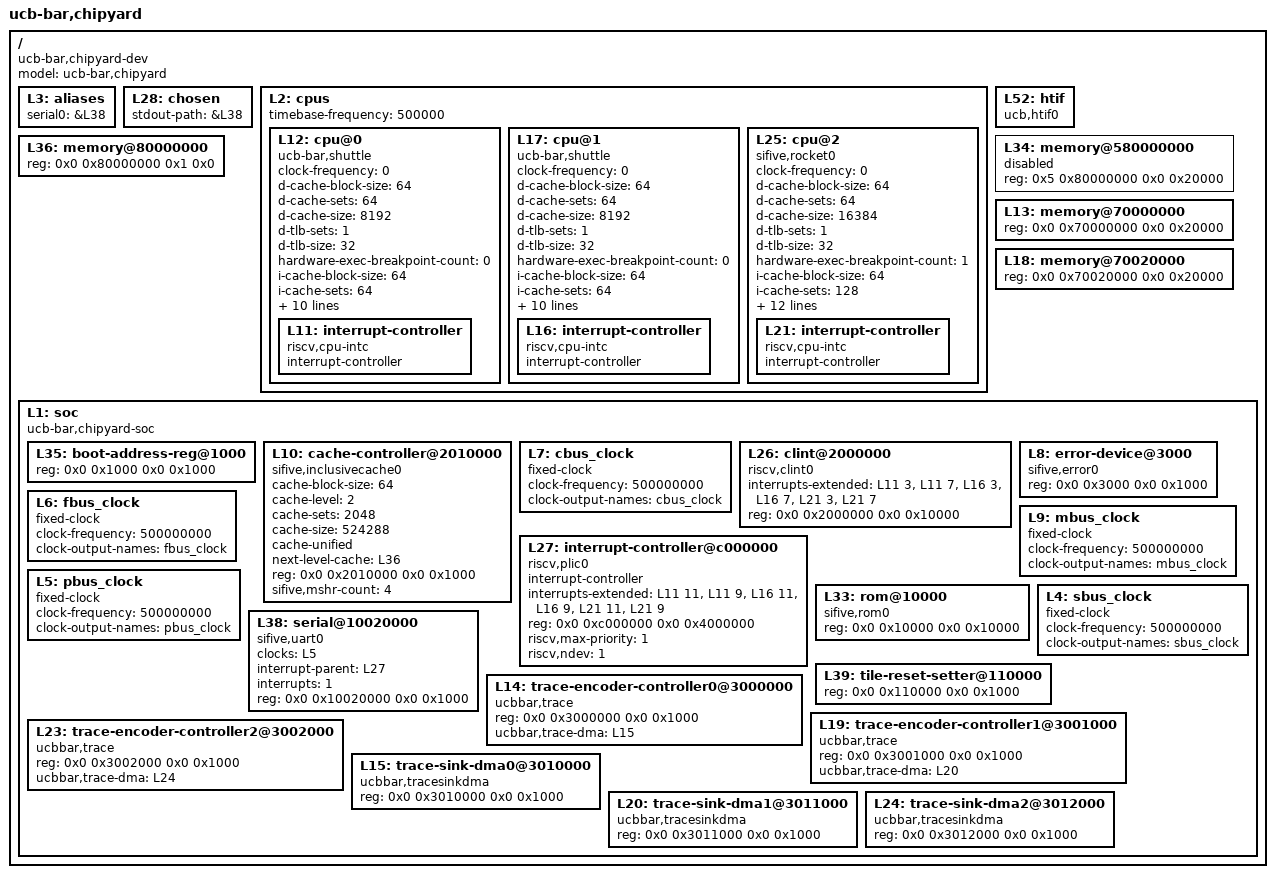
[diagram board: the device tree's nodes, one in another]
/dts-v1/;

/ {
	#address-cells = <2>;
	#size-cells = <2>;
	compatible = "ucb-bar,chipyard-dev";
	model = "ucb-bar,chipyard";
	L3: aliases {
		serial0 = &L38;
	};
	L28: chosen {
		stdout-path = &L38;
	};
	L2: cpus {
		#address-cells = <1>;
		#size-cells = <0>;
		timebase-frequency = <500000>;
		L12: cpu@0 {
			clock-frequency = <0>;
			compatible = "ucb-bar,shuttle", "riscv";
			d-cache-block-size = <64>;
			d-cache-sets = <64>;
			d-cache-size = <8192>;
			d-tlb-sets = <1>;
			d-tlb-size = <32>;
			device_type = "cpu";
			hardware-exec-breakpoint-count = <0>;
			i-cache-block-size = <64>;
			i-cache-sets = <64>;
			i-cache-size = <8192>;
			i-tlb-sets = <1>;
			i-tlb-size = <32>;
			mmu-type = "riscv,sv39";
			next-level-cache = <&L10>;
			reg = <0x0>;
			riscv,isa = "rv64imafdcbvzicsr_zifencei_zihpm_zvl256b_zve64d_zvfh_zfh_zba_zbb_zbs_zvbb_zvfofp8min_zfbfmin_zvfbfmin_zvfbfa_xsfmmbase_xsfmm32a8i_xsfmm32a8f_xsfmm32t";
			status = "okay";
			timebase-frequency = <500000>;
			tlb-split;
			L11: interrupt-controller {
				#interrupt-cells = <1>;
				compatible = "riscv,cpu-intc";
				interrupt-controller;
			};
		};
		L17: cpu@1 {
			clock-frequency = <0>;
			compatible = "ucb-bar,shuttle", "riscv";
			d-cache-block-size = <64>;
			d-cache-sets = <64>;
			d-cache-size = <8192>;
			d-tlb-sets = <1>;
			d-tlb-size = <32>;
			device_type = "cpu";
			hardware-exec-breakpoint-count = <0>;
			i-cache-block-size = <64>;
			i-cache-sets = <64>;
			i-cache-size = <8192>;
			i-tlb-sets = <1>;
			i-tlb-size = <32>;
			mmu-type = "riscv,sv39";
			next-level-cache = <&L10>;
			reg = <0x1>;
			riscv,isa = "rv64imafdcbvzicsr_zifencei_zihpm_zvl256b_zve64d_zvfh_zfh_zba_zbb_zbs_zvbb_zvfofp8min_zfbfmin_zvfbfmin_zvfbfa_xsfmmbase_xsfmm32a8i_xsfmm32a8f_xsfmm32t";
			status = "okay";
			timebase-frequency = <500000>;
			tlb-split;
			L16: interrupt-controller {
				#interrupt-cells = <1>;
				compatible = "riscv,cpu-intc";
				interrupt-controller;
			};
		};
		L25: cpu@2 {
			clock-frequency = <0>;
			compatible = "sifive,rocket0", "riscv";
			d-cache-block-size = <64>;
			d-cache-sets = <64>;
			d-cache-size = <16384>;
			d-tlb-sets = <1>;
			d-tlb-size = <32>;
			device_type = "cpu";
			hardware-exec-breakpoint-count = <1>;
			i-cache-block-size = <64>;
			i-cache-sets = <128>;
			i-cache-size = <16384>;
			i-tlb-sets = <1>;
			i-tlb-size = <32>;
			mmu-type = "riscv,sv39";
			next-level-cache = <&L10>;
			reg = <0x2>;
			riscv,isa = "rv64imafdcvzicsr_zifencei_zihpm_zvl256b_zve64d_zvfh_zfh_zvbb_xrocket";
			riscv,pmpgranularity = <4>;
			riscv,pmpregions = <8>;
			status = "okay";
			timebase-frequency = <500000>;
			tlb-split;
			L21: interrupt-controller {
				#interrupt-cells = <1>;
				compatible = "riscv,cpu-intc";
				interrupt-controller;
			};
		};
	};
	L52: htif {
		compatible = "ucb,htif0";
	};
	L34: memory@580000000 {
		device_type = "memory";
		reg = <0x5 0x80000000 0x0 0x20000>;
		status = "disabled";
	};
	L13: memory@70000000 {
		device_type = "memory";
		reg = <0x0 0x70000000 0x0 0x20000>;
	};
	L18: memory@70020000 {
		device_type = "memory";
		reg = <0x0 0x70020000 0x0 0x20000>;
	};
	L36: memory@80000000 {
		device_type = "memory";
		reg = <0x0 0x80000000 0x1 0x0>;
	};
	L1: soc {
		#address-cells = <2>;
		#size-cells = <2>;
		compatible = "ucb-bar,chipyard-soc", "simple-bus";
		ranges;
		L35: boot-address-reg@1000 {
			reg = <0x0 0x1000 0x0 0x1000>;
			reg-names = "control";
		};
		L10: cache-controller@2010000 {
			cache-block-size = <64>;
			cache-level = <2>;
			cache-sets = <2048>;
			cache-size = <524288>;
			cache-unified;
			compatible = "sifive,inclusivecache0", "cache";
			next-level-cache = <&L36>;
			reg = <0x0 0x2010000 0x0 0x1000>;
			reg-names = "control";
			sifive,mshr-count = <4>;
		};
		L7: cbus_clock {
			#clock-cells = <0>;
			clock-frequency = <500000000>;
			clock-output-names = "cbus_clock";
			compatible = "fixed-clock";
		};
		L26: clint@2000000 {
			compatible = "riscv,clint0";
			interrupts-extended = <&L11 3 &L11 7 &L16 3 &L16 7 &L21 3 &L21 7>;
			reg = <0x0 0x2000000 0x0 0x10000>;
			reg-names = "control";
		};
		L8: error-device@3000 {
			compatible = "sifive,error0";
			reg = <0x0 0x3000 0x0 0x1000>;
		};
		L6: fbus_clock {
			#clock-cells = <0>;
			clock-frequency = <500000000>;
			clock-output-names = "fbus_clock";
			compatible = "fixed-clock";
		};
		L27: interrupt-controller@c000000 {
			#interrupt-cells = <1>;
			compatible = "riscv,plic0";
			interrupt-controller;
			interrupts-extended = <&L11 11 &L11 9 &L16 11 &L16 9 &L21 11 &L21 9>;
			reg = <0x0 0xc000000 0x0 0x4000000>;
			reg-names = "control";
			riscv,max-priority = <1>;
			riscv,ndev = <1>;
		};
		L9: mbus_clock {
			#clock-cells = <0>;
			clock-frequency = <500000000>;
			clock-output-names = "mbus_clock";
			compatible = "fixed-clock";
		};
		L5: pbus_clock {
			#clock-cells = <0>;
			clock-frequency = <500000000>;
			clock-output-names = "pbus_clock";
			compatible = "fixed-clock";
		};
		L33: rom@10000 {
			compatible = "sifive,rom0";
			reg = <0x0 0x10000 0x0 0x10000>;
			reg-names = "mem";
		};
		L4: sbus_clock {
			#clock-cells = <0>;
			clock-frequency = <500000000>;
			clock-output-names = "sbus_clock";
			compatible = "fixed-clock";
		};
		L38: serial@10020000 {
			clocks = <&L5>;
			compatible = "sifive,uart0";
			interrupt-parent = <&L27>;
			interrupts = <1>;
			reg = <0x0 0x10020000 0x0 0x1000>;
			reg-names = "control";
		};
		L39: tile-reset-setter@110000 {
			reg = <0x0 0x110000 0x0 0x1000>;
			reg-names = "control";
		};
		L14: trace-encoder-controller0@3000000 {
			compatible = "ucbbar,trace";
			reg = <0x0 0x3000000 0x0 0x1000>;
			reg-names = "control";
			ucbbar,trace-dma = <&L15>;
		};
		L19: trace-encoder-controller1@3001000 {
			compatible = "ucbbar,trace";
			reg = <0x0 0x3001000 0x0 0x1000>;
			reg-names = "control";
			ucbbar,trace-dma = <&L20>;
		};
		L23: trace-encoder-controller2@3002000 {
			compatible = "ucbbar,trace";
			reg = <0x0 0x3002000 0x0 0x1000>;
			reg-names = "control";
			ucbbar,trace-dma = <&L24>;
		};
		L15: trace-sink-dma0@3010000 {
			compatible = "ucbbar,tracesinkdma";
			reg = <0x0 0x3010000 0x0 0x1000>;
			reg-names = "control";
		};
		L20: trace-sink-dma1@3011000 {
			compatible = "ucbbar,tracesinkdma";
			reg = <0x0 0x3011000 0x0 0x1000>;
			reg-names = "control";
		};
		L24: trace-sink-dma2@3012000 {
			compatible = "ucbbar,tracesinkdma";
			reg = <0x0 0x3012000 0x0 0x1000>;
			reg-names = "control";
		};
	};
};
